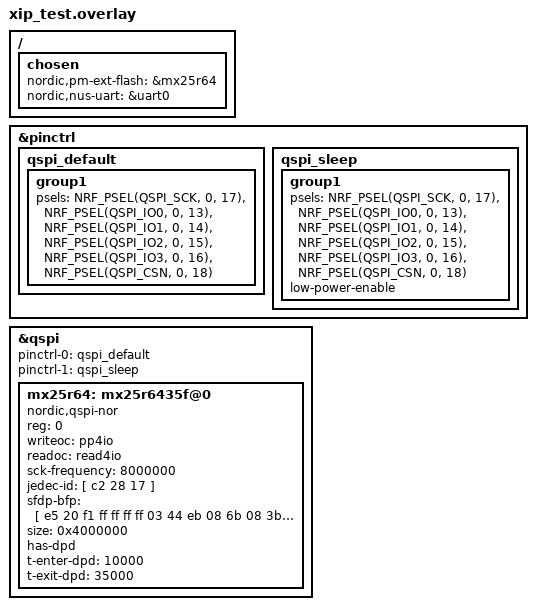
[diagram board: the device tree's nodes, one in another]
/ {
	chosen {
		nordic,pm-ext-flash = &mx25r64;
		nordic,nus-uart = &uart0;
		// Remove display for XIP testing
		// zephyr,display = &hls12vga;
	};
};

&pinctrl {
    qspi_default: qspi_default {
        group1 {
            psels = <NRF_PSEL(QSPI_SCK, 0, 17)>,
                    <NRF_PSEL(QSPI_IO0, 0, 13)>,
                    <NRF_PSEL(QSPI_IO1, 0, 14)>,
                    <NRF_PSEL(QSPI_IO2, 0, 15)>,
                    <NRF_PSEL(QSPI_IO3, 0, 16)>,
                    <NRF_PSEL(QSPI_CSN, 0, 18)>;
        };
    };

    qspi_sleep: qspi_sleep {
        group1 {
            psels = <NRF_PSEL(QSPI_SCK, 0, 17)>,
                    <NRF_PSEL(QSPI_IO0, 0, 13)>,
                    <NRF_PSEL(QSPI_IO1, 0, 14)>,
                    <NRF_PSEL(QSPI_IO2, 0, 15)>,
                    <NRF_PSEL(QSPI_IO3, 0, 16)>,
                    <NRF_PSEL(QSPI_CSN, 0, 18)>;
            low-power-enable;
        };
    };
};

&qspi {
    status = "okay";
    pinctrl-0 = <&qspi_default>;
    pinctrl-1 = <&qspi_sleep>;
    pinctrl-names = "default", "sleep";
    mx25r64: mx25r6435f@0 {
        compatible = "nordic,qspi-nor";
        reg = <0>;
        /* MX25R64 supports only pp and pp4io */
        writeoc = "pp4io";
        /* MX25R64 supports all readoc options */
        readoc = "read4io";
        sck-frequency = <8000000>;
        jedec-id = [ c2 28 17  ];
        sfdp-bfp = [ e5 20 f1 ff ff ff ff 03 44 eb 08 6b 08 3b 04 bb ee ff ff ff ff ff 00 ff ff ff 00 ff 0c 20 0f 52 10 d8 00 ff 23 72 f5 00 82 ed 04 cc 44 83 68 44 30 b0 30 b0 f7 c4 d5 5c 00 be 29 ff f0 d0 ff ff  ];
        size = <0x4000000>;
        has-dpd;
        t-enter-dpd = <10000>;
        t-exit-dpd = <35000>;
    };
};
